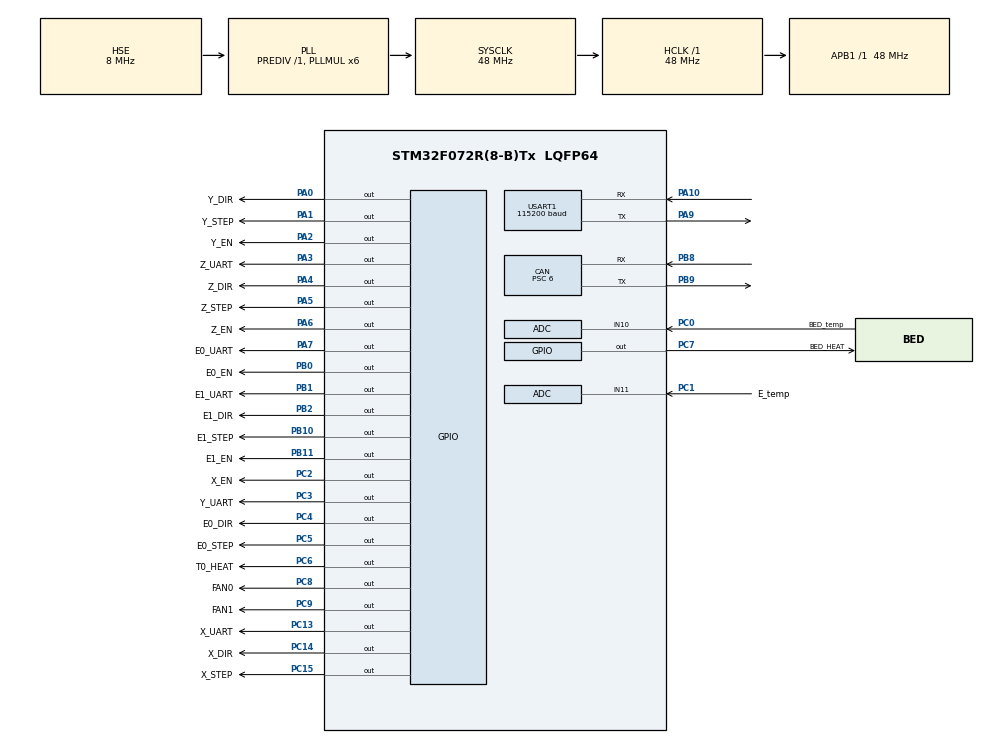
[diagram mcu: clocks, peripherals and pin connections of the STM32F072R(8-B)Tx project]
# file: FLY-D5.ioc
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CAN.BS1=CAN_BS1_13TQ
CAN.BS2=CAN_BS2_2TQ
CAN.CalculateBaudRate=500000
CAN.CalculateTimeBit=2000
CAN.CalculateTimeQuantum=125.0
CAN.NART=ENABLE
CAN.Prescaler=6
IWDG.Reload=640
IWDG.Window=640
Mcu.Family=STM32F0
Mcu.Name=STM32F072R(8-B)Tx
Mcu.Package=LQFP64
NVIC.CEC_CAN_IRQn=true\:3\:0\:true\:false\:true\:true\:true\:true
NVIC.TIM2_IRQn=true\:2\:0\:true\:false\:true\:true\:true\:true
NVIC.TIM7_IRQn=true\:3\:0\:true\:false\:true\:true\:true\:true
NVIC.USART1_IRQn=true\:3\:0\:true\:false\:true\:true\:true\:true
PA0.GPIO_Label=Y_DIR
PA0.Signal=GPIO_Output
PA1.GPIO_Label=Y_STEP
PA1.Signal=GPIO_Output
PA10.GPIO_PuPd=GPIO_PULLUP
PA10.Mode=Asynchronous
PA10.Signal=USART1_RX
PA13.GPIO_Label=SWDIO/LCD_D5
PA13.Mode=Serial_Wire
PA13.Signal=SYS_SWDIO
PA14.GPIO_Label=SW_CLK/LCD_RS
PA14.Mode=Serial_Wire
PA14.Signal=SYS_SWCLK
PA2.GPIO_Label=Y_EN
PA2.PinState=GPIO_PIN_SET
PA2.Signal=GPIO_Output
PA3.GPIO_Label=Z_UART
PA3.PinState=GPIO_PIN_SET
PA3.Signal=GPIO_Output
PA4.GPIO_Label=Z_DIR
PA4.Signal=GPIO_Output
PA5.GPIO_Label=Z_STEP
PA5.Signal=GPIO_Output
PA6.GPIO_Label=Z_EN
PA6.PinState=GPIO_PIN_SET
PA6.Signal=GPIO_Output
PA7.GPIO_Label=E0_UART
PA7.PinState=GPIO_PIN_SET
PA7.Signal=GPIO_Output
PA9.Mode=Asynchronous
PA9.Signal=USART1_TX
PB0.GPIO_Label=E0_EN
PB0.PinState=GPIO_PIN_SET
PB0.Signal=GPIO_Output
PB1.GPIO_Label=E1_UART
PB1.PinState=GPIO_PIN_SET
PB1.Signal=GPIO_Output
PB10.GPIO_Label=E1_STEP
PB10.Signal=GPIO_Output
PB11.GPIO_Label=E1_EN
PB11.PinState=GPIO_PIN_SET
PB11.Signal=GPIO_Output
PB2.GPIO_Label=E1_DIR
PB2.Signal=GPIO_Output
PB8.Mode=CAN_Activate
PB8.Signal=CAN_RX
PB9.Mode=CAN_Activate
PB9.Signal=CAN_TX
PC0.GPIO_Label=BED_temp
PC0.Mode=IN10
PC0.Signal=ADC_IN10
PC1.GPIO_Label=E_temp
PC1.Mode=IN11
PC1.Signal=ADC_IN11
PC13.GPIO_Label=X_UART
PC13.PinState=GPIO_PIN_SET
PC13.Signal=GPIO_Output
PC14-OSC32_IN.GPIO_Label=X_DIR
PC14-OSC32_IN.Signal=GPIO_Output
PC15-OSC32_OUT.GPIO_Label=X_STEP
PC15-OSC32_OUT.Signal=GPIO_Output
PC2.GPIO_Label=X_EN
PC2.PinState=GPIO_PIN_SET
PC2.Signal=GPIO_Output
PC3.GPIO_Label=Y_UART
PC3.PinState=GPIO_PIN_SET
PC3.Signal=GPIO_Output
PC4.GPIO_Label=E0_DIR
PC4.Signal=GPIO_Output
PC5.GPIO_Label=E0_STEP
PC5.Signal=GPIO_Output
PC6.GPIO_Label=T0_HEAT
PC6.Signal=GPIO_Output
PC7.GPIO_Label=BED_HEAT
PC7.Signal=GPIO_Output
PC8.GPIO_Label=FAN0
PC8.Signal=GPIO_Output
PC9.GPIO_Label=FAN1
PC9.Signal=GPIO_Output
PF0-OSC_IN.Mode=HSE-External-Oscillator
PF0-OSC_IN.Signal=RCC_OSC_IN
PF1-OSC_OUT.Mode=HSE-External-Oscillator
PF1-OSC_OUT.Signal=RCC_OSC_OUT
ProjectManager.HeapSize=0x200
ProjectManager.StackSize=0x400
ProjectManager.TargetToolchain=STM32CubeIDE
RCC.AHBFreq_Value=48000000
RCC.APB1Freq_Value=48000000
RCC.APB1TimFreq_Value=48000000
RCC.HCLKFreq_Value=48000000
RCC.PLLMUL=RCC_PLL_MUL6
RCC.PLLSourceVirtual=RCC_PLLSOURCE_HSE
RCC.SYSCLKFreq_VALUE=48000000
RCC.SYSCLKSource=RCC_SYSCLKSOURCE_PLLCLK
TIM2.Period=9
TIM2.Prescaler=47
TIM6.Prescaler=47
TIM7.Period=999
TIM7.Prescaler=47
USART1.BaudRate=115200
USART1.VirtualMode-Asynchronous=VM_ASYNC
VP_IWDG_VS_IWDG.Mode=IWDG_Activate
VP_TIM2_VS_ClockSourceINT.Mode=Internal
VP_TIM6_VS_ClockSourceINT.Mode=Enable_Timer
VP_TIM7_VS_ClockSourceINT.Mode=Enable_Timer
board=custom

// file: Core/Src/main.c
/* USER CODE BEGIN Header */
/**
  ******************************************************************************
  * @file           : main.c
  * @brief          : Main program body
  ******************************************************************************
  * @attention
  *
  * Copyright (c) 2025 STMicroelectronics.
  * All rights reserved.
  *
  * This software is licensed under terms that can be found in the LICENSE file
  * in the root directory of this software component.
  * If no LICENSE file comes with this software, it is provided AS-IS.
  *
  ******************************************************************************
  */
/* USER CODE END Header */
#include "main.h"

/* USER CODE BEGIN Includes */
#include "scheduler.h"
/* USER CODE END Includes */

ADC_HandleTypeDef hadc;

CAN_HandleTypeDef hcan;

IWDG_HandleTypeDef hiwdg;

TIM_HandleTypeDef htim6;

UART_HandleTypeDef huart1;

void SystemClock_Config(void);
static void MX_GPIO_Init(void);
static void MX_ADC_Init(void);
static void MX_CAN_Init(void);
static void MX_IWDG_Init(void);
static void MX_TIM2_Init(void);
static void MX_TIM7_Init(void);
static void MX_TIM6_Init(void);
static void MX_USART1_UART_Init(void);

int main(void)
{

  /* MCU Configuration--------------------------------------------------------*/

  /* Reset of all peripherals, Initializes the Flash interface and the Systick. */
  HAL_Init();

  /* Configure the system clock */
  SystemClock_Config();

  /* Initialize all configured peripherals */
  MX_GPIO_Init();
  MX_ADC_Init();
  MX_CAN_Init();
  //MX_IWDG_Init();
  MX_TIM2_Init();
  MX_TIM7_Init();
  MX_TIM6_Init();
  MX_USART1_UART_Init();
  /* USER CODE BEGIN 2 */
  motor_control_init();
  /* USER CODE END 2 */

  /* Infinite loop */
  /* USER CODE BEGIN WHILE */
  while (1)
  {
	do_motor_control_tasks();
    /* USER CODE END WHILE */

  }
}

void SystemClock_Config(void)
{
  RCC_OscInitTypeDef RCC_OscInitStruct = {0};
  RCC_ClkInitTypeDef RCC_ClkInitStruct = {0};
  RCC_PeriphCLKInitTypeDef PeriphClkInit = {0};

  /** Initializes the RCC Oscillators according to the specified parameters
  * in the RCC_OscInitTypeDef structure.
  */
  RCC_OscInitStruct.OscillatorType = RCC_OSCILLATORTYPE_HSI14|RCC_OSCILLATORTYPE_LSI
                              |RCC_OSCILLATORTYPE_HSE;
  RCC_OscInitStruct.HSEState = RCC_HSE_ON;
  RCC_OscInitStruct.HSI14State = RCC_HSI14_ON;
  RCC_OscInitStruct.HSI14CalibrationValue = 16;
  RCC_OscInitStruct.LSIState = RCC_LSI_ON;
  RCC_OscInitStruct.PLL.PLLState = RCC_PLL_ON;
  RCC_OscInitStruct.PLL.PLLSource = RCC_PLLSOURCE_HSE;
  RCC_OscInitStruct.PLL.PLLMUL = RCC_PLL_MUL6;
  RCC_OscInitStruct.PLL.PREDIV = RCC_PREDIV_DIV1;
  if (HAL_RCC_OscConfig(&RCC_OscInitStruct) != HAL_OK)
  {
    Error_Handler();
  }

  /** Initializes the CPU, AHB and APB buses clocks
  */
  RCC_ClkInitStruct.ClockType = RCC_CLOCKTYPE_HCLK|RCC_CLOCKTYPE_SYSCLK
                              |RCC_CLOCKTYPE_PCLK1;
  RCC_ClkInitStruct.SYSCLKSource = RCC_SYSCLKSOURCE_PLLCLK;
  RCC_ClkInitStruct.AHBCLKDivider = RCC_SYSCLK_DIV1;
  RCC_ClkInitStruct.APB1CLKDivider = RCC_HCLK_DIV1;

  if (HAL_RCC_ClockConfig(&RCC_ClkInitStruct, FLASH_LATENCY_1) != HAL_OK)
  {
    Error_Handler();
  }
  PeriphClkInit.PeriphClockSelection = RCC_PERIPHCLK_USART1;
  PeriphClkInit.Usart1ClockSelection = RCC_USART1CLKSOURCE_PCLK1;
  if (HAL_RCCEx_PeriphCLKConfig(&PeriphClkInit) != HAL_OK)
  {
    Error_Handler();
  }
}

static void MX_ADC_Init(void)
{

  ADC_ChannelConfTypeDef sConfig = {0};

  /** Configure the global features of the ADC (Clock, Resolution, Data Alignment and number of conversion)
  */
  hadc.Instance = ADC1;
  hadc.Init.ClockPrescaler = ADC_CLOCK_ASYNC_DIV1;
  hadc.Init.Resolution = ADC_RESOLUTION_12B;
  hadc.Init.DataAlign = ADC_DATAALIGN_RIGHT;
  hadc.Init.ScanConvMode = ADC_SCAN_DIRECTION_FORWARD;
  hadc.Init.EOCSelection = ADC_EOC_SINGLE_CONV;
  hadc.Init.LowPowerAutoWait = DISABLE;
  hadc.Init.LowPowerAutoPowerOff = DISABLE;
  hadc.Init.ContinuousConvMode = DISABLE;
  hadc.Init.DiscontinuousConvMode = DISABLE;
  hadc.Init.ExternalTrigConv = ADC_SOFTWARE_START;
  hadc.Init.ExternalTrigConvEdge = ADC_EXTERNALTRIGCONVEDGE_NONE;
  hadc.Init.DMAContinuousRequests = DISABLE;
  hadc.Init.Overrun = ADC_OVR_DATA_PRESERVED;
  if (HAL_ADC_Init(&hadc) != HAL_OK)
  {
    Error_Handler();
  }

  /** Configure for the selected ADC regular channel to be converted.
  */
  sConfig.Channel = ADC_CHANNEL_10;
  sConfig.Rank = ADC_RANK_CHANNEL_NUMBER;
  sConfig.SamplingTime = ADC_SAMPLETIME_1CYCLE_5;
  if (HAL_ADC_ConfigChannel(&hadc, &sConfig) != HAL_OK)
  {
    Error_Handler();
  }

  /** Configure for the selected ADC regular channel to be converted.
  */
  sConfig.Channel = ADC_CHANNEL_11;
  if (HAL_ADC_ConfigChannel(&hadc, &sConfig) != HAL_OK)
  {
    Error_Handler();
  }

}

static void MX_CAN_Init(void)
{

  hcan.Instance = CAN;
  hcan.Init.Prescaler = 6;
  hcan.Init.Mode = CAN_MODE_NORMAL;
  hcan.Init.SyncJumpWidth = CAN_SJW_1TQ;
  hcan.Init.TimeSeg1 = CAN_BS1_13TQ;
  hcan.Init.TimeSeg2 = CAN_BS2_2TQ;
  hcan.Init.TimeTriggeredMode = DISABLE;
  hcan.Init.AutoBusOff = DISABLE;
  hcan.Init.AutoWakeUp = DISABLE;
  hcan.Init.AutoRetransmission = ENABLE;
  hcan.Init.ReceiveFifoLocked = DISABLE;
  hcan.Init.TransmitFifoPriority = DISABLE;
  if (HAL_CAN_Init(&hcan) != HAL_OK)
  {
    Error_Handler();
  }

}

static void MX_IWDG_Init(void)
{

  hiwdg.Instance = IWDG;
  hiwdg.Init.Prescaler = IWDG_PRESCALER_4;
  hiwdg.Init.Window = 640;
  hiwdg.Init.Reload = 640;
  if (HAL_IWDG_Init(&hiwdg) != HAL_OK)
  {
    Error_Handler();
  }

}

static void MX_TIM2_Init(void)
{

  LL_TIM_InitTypeDef TIM_InitStruct = {0};

  /* Peripheral clock enable */
  LL_APB1_GRP1_EnableClock(LL_APB1_GRP1_PERIPH_TIM2);

  /* TIM2 interrupt Init */
  NVIC_SetPriority(TIM2_IRQn, 2);
  NVIC_EnableIRQ(TIM2_IRQn);

  TIM_InitStruct.Prescaler = 47;
  TIM_InitStruct.CounterMode = LL_TIM_COUNTERMODE_UP;
  TIM_InitStruct.Autoreload = 9;
  TIM_InitStruct.ClockDivision = LL_TIM_CLOCKDIVISION_DIV1;
  LL_TIM_Init(TIM2, &TIM_InitStruct);
  LL_TIM_DisableARRPreload(TIM2);
  LL_TIM_SetClockSource(TIM2, LL_TIM_CLOCKSOURCE_INTERNAL);
  LL_TIM_SetTriggerOutput(TIM2, LL_TIM_TRGO_RESET);
  LL_TIM_DisableMasterSlaveMode(TIM2);

}

static void MX_TIM6_Init(void)
{

  TIM_MasterConfigTypeDef sMasterConfig = {0};

  htim6.Instance = TIM6;
  htim6.Init.Prescaler = 47;
  htim6.Init.CounterMode = TIM_COUNTERMODE_UP;
  htim6.Init.Period = 65535;
  htim6.Init.AutoReloadPreload = TIM_AUTORELOAD_PRELOAD_DISABLE;
  if (HAL_TIM_Base_Init(&htim6) != HAL_OK)
  {
    Error_Handler();
  }
  sMasterConfig.MasterOutputTrigger = TIM_TRGO_RESET;
  sMasterConfig.MasterSlaveMode = TIM_MASTERSLAVEMODE_DISABLE;
  if (HAL_TIMEx_MasterConfigSynchronization(&htim6, &sMasterConfig) != HAL_OK)
  {
    Error_Handler();
  }

}

static void MX_TIM7_Init(void)
{

  LL_TIM_InitTypeDef TIM_InitStruct = {0};

  /* Peripheral clock enable */
  LL_APB1_GRP1_EnableClock(LL_APB1_GRP1_PERIPH_TIM7);

  /* TIM7 interrupt Init */
  NVIC_SetPriority(TIM7_IRQn, 3);
  NVIC_EnableIRQ(TIM7_IRQn);

  TIM_InitStruct.Prescaler = 47;
  TIM_InitStruct.CounterMode = LL_TIM_COUNTERMODE_UP;
  TIM_InitStruct.Autoreload = 999;
  LL_TIM_Init(TIM7, &TIM_InitStruct);
  LL_TIM_DisableARRPreload(TIM7);
  LL_TIM_SetTriggerOutput(TIM7, LL_TIM_TRGO_RESET);
  LL_TIM_DisableMasterSlaveMode(TIM7);

}

static void MX_USART1_UART_Init(void)
{

  huart1.Instance = USART1;
  huart1.Init.BaudRate = 115200;
  huart1.Init.WordLength = UART_WORDLENGTH_8B;
  huart1.Init.StopBits = UART_STOPBITS_1;
  huart1.Init.Parity = UART_PARITY_NONE;
  huart1.Init.Mode = UART_MODE_TX_RX;
  huart1.Init.HwFlowCtl = UART_HWCONTROL_NONE;
  huart1.Init.OverSampling = UART_OVERSAMPLING_16;
  huart1.Init.OneBitSampling = UART_ONE_BIT_SAMPLE_DISABLE;
  huart1.AdvancedInit.AdvFeatureInit = UART_ADVFEATURE_NO_INIT;
  if (HAL_UART_Init(&huart1) != HAL_OK)
  {
    Error_Handler();
  }

}

static void MX_GPIO_Init(void)
{
  GPIO_InitTypeDef GPIO_InitStruct = {0};

  /* GPIO Ports Clock Enable */
  __HAL_RCC_GPIOC_CLK_ENABLE();
  __HAL_RCC_GPIOF_CLK_ENABLE();
  __HAL_RCC_GPIOA_CLK_ENABLE();
  __HAL_RCC_GPIOB_CLK_ENABLE();

  /*Configure GPIO pin Output Level */
  HAL_GPIO_WritePin(GPIOC, X_UART_Pin|X_EN_Pin|Y_UART_Pin, GPIO_PIN_SET);

  /*Configure GPIO pin Output Level */
  HAL_GPIO_WritePin(GPIOC, X_DIR_Pin|X_STEP_Pin|E0_DIR_Pin|E0_STEP_Pin
                          |T0_HEAT_Pin|BED_HEAT_Pin|FAN0_Pin|FAN1_Pin, GPIO_PIN_RESET);

  /*Configure GPIO pin Output Level */
  HAL_GPIO_WritePin(GPIOA, Y_DIR_Pin|Y_STEP_Pin|Z_DIR_Pin|Z_STEP_Pin, GPIO_PIN_RESET);

  /*Configure GPIO pin Output Level */
  HAL_GPIO_WritePin(GPIOA, Y_EN_Pin|Z_UART_Pin|Z_EN_Pin|E0_UART_Pin, GPIO_PIN_SET);

  /*Configure GPIO pin Output Level */
  HAL_GPIO_WritePin(GPIOB, E0_EN_Pin|E1_UART_Pin|E1_EN_Pin, GPIO_PIN_SET);

  /*Configure GPIO pin Output Level */
  HAL_GPIO_WritePin(GPIOB, E1_DIR_Pin|E1_STEP_Pin, GPIO_PIN_RESET);

  /*Configure GPIO pins : X_UART_Pin X_DIR_Pin X_STEP_Pin X_EN_Pin
                           Y_UART_Pin E0_DIR_Pin E0_STEP_Pin T0_HEAT_Pin
                           BED_HEAT_Pin FAN0_Pin FAN1_Pin */
  GPIO_InitStruct.Pin = X_UART_Pin|X_DIR_Pin|X_STEP_Pin|X_EN_Pin
                          |Y_UART_Pin|E0_DIR_Pin|E0_STEP_Pin|T0_HEAT_Pin
                          |BED_HEAT_Pin|FAN0_Pin|FAN1_Pin;
  GPIO_InitStruct.Mode = GPIO_MODE_OUTPUT_PP;
  GPIO_InitStruct.Pull = GPIO_NOPULL;
  GPIO_InitStruct.Speed = GPIO_SPEED_FREQ_LOW;
  HAL_GPIO_Init(GPIOC, &GPIO_InitStruct);

  /*Configure GPIO pins : Y_DIR_Pin Y_STEP_Pin Y_EN_Pin Z_UART_Pin
                           Z_DIR_Pin Z_STEP_Pin Z_EN_Pin E0_UART_Pin */
  GPIO_InitStruct.Pin = Y_DIR_Pin|Y_STEP_Pin|Y_EN_Pin|Z_UART_Pin
                          |Z_DIR_Pin|Z_STEP_Pin|Z_EN_Pin|E0_UART_Pin;
  GPIO_InitStruct.Mode = GPIO_MODE_OUTPUT_PP;
  GPIO_InitStruct.Pull = GPIO_NOPULL;
  GPIO_InitStruct.Speed = GPIO_SPEED_FREQ_LOW;
  HAL_GPIO_Init(GPIOA, &GPIO_InitStruct);

  /*Configure GPIO pins : E0_EN_Pin E1_UART_Pin E1_DIR_Pin E1_STEP_Pin
                           E1_EN_Pin */
  GPIO_InitStruct.Pin = E0_EN_Pin|E1_UART_Pin|E1_DIR_Pin|E1_STEP_Pin
                          |E1_EN_Pin;
  GPIO_InitStruct.Mode = GPIO_MODE_OUTPUT_PP;
  GPIO_InitStruct.Pull = GPIO_NOPULL;
  GPIO_InitStruct.Speed = GPIO_SPEED_FREQ_LOW;
  HAL_GPIO_Init(GPIOB, &GPIO_InitStruct);

}

void Error_Handler(void)
{
  __disable_irq();
  while (1)
  {
  }
}
